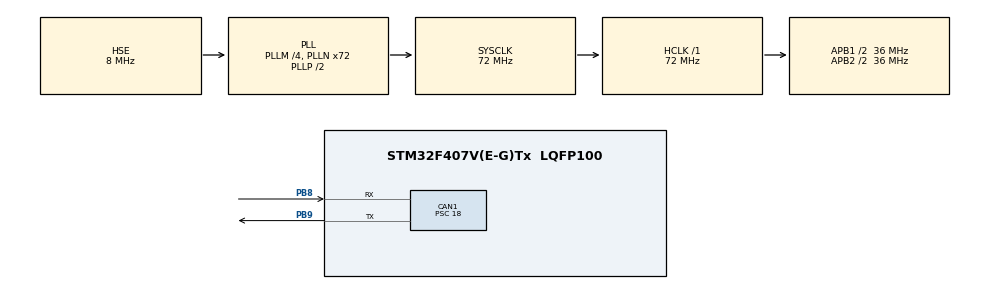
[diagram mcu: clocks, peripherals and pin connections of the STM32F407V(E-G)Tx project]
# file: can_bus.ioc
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CAN1.BS1=CAN_BS1_2TQ
CAN1.CalculateBaudRate=500000
CAN1.CalculateTimeBit=2000
CAN1.CalculateTimeQuantum=500.0
CAN1.Mode=CAN_MODE_LOOPBACK
CAN1.Prescaler=18
Mcu.Family=STM32F4
Mcu.Name=STM32F407V(E-G)Tx
Mcu.Package=LQFP100
NVIC.CAN1_RX0_IRQn=true\:0\:0\:false\:false\:true\:true\:true\:true
NVIC.PriorityGroup=NVIC_PRIORITYGROUP_0
PB8.Mode=CAN_Activate
PB8.Signal=CAN1_RX
PB9.Mode=CAN_Activate
PB9.Signal=CAN1_TX
PH0-OSC_IN.Mode=HSE-External-Oscillator
PH0-OSC_IN.Signal=RCC_OSC_IN
PH1-OSC_OUT.Mode=HSE-External-Oscillator
PH1-OSC_OUT.Signal=RCC_OSC_OUT
ProjectManager.HeapSize=0x200
ProjectManager.StackSize=0x400
ProjectManager.TargetToolchain=STM32CubeIDE
RCC.48MHZClocksFreq_Value=20571428.57142857
RCC.AHBFreq_Value=72000000
RCC.APB1CLKDivider=RCC_HCLK_DIV2
RCC.APB1Freq_Value=36000000
RCC.APB1TimFreq_Value=72000000
RCC.APB2CLKDivider=RCC_HCLK_DIV2
RCC.APB2Freq_Value=36000000
RCC.APB2TimFreq_Value=72000000
RCC.CortexFreq_Value=72000000
RCC.HCLKFreq_Value=72000000
RCC.HSE_VALUE=8000000
RCC.HSI_VALUE=16000000
RCC.LSE_VALUE=32768
RCC.PLLM=4
RCC.PLLN=72
RCC.PLLQ=7
RCC.PLLSourceVirtual=RCC_PLLSOURCE_HSE
RCC.SYSCLKFreq_VALUE=72000000
RCC.SYSCLKSource=RCC_SYSCLKSOURCE_PLLCLK
RCC.VCOOutputFreq_Value=144000000
board=STM32F407G-DISC1

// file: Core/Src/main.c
/* USER CODE BEGIN Header */
/**
  ******************************************************************************
  * @file           : main.c
  * @brief          : Main program body
  ******************************************************************************
  * @attention
  *
  * Copyright (c) 2023 STMicroelectronics.
  * All rights reserved.
  *
  * This software is licensed under terms that can be found in the LICENSE file
  * in the root directory of this software component.
  * If no LICENSE file comes with this software, it is provided AS-IS.
  *
  ******************************************************************************
  */
/* USER CODE END Header */
#include "main.h"

CAN_HandleTypeDef hcan1;

/* USER CODE BEGIN PV */
uint8_t RxData[8];
CAN_RxHeaderTypeDef RxHeader;
uint8_t TxData[8];
CAN_TxHeaderTypeDef TxHeader;
/* USER CODE END PV */

void SystemClock_Config(void);
static void MX_GPIO_Init(void);
static void MX_CAN1_Init(void);

int main(void)
{

  /* MCU Configuration--------------------------------------------------------*/

  /* Reset of all peripherals, Initializes the Flash interface and the Systick. */
  HAL_Init();

  /* Configure the system clock */
  SystemClock_Config();

  /* Initialize all configured peripherals */
  MX_GPIO_Init();
  MX_CAN1_Init();
  /* USER CODE BEGIN 2 */
  if(HAL_CAN_Start(&hcan1) != HAL_OK)
	  Error_Handler();

  if(HAL_CAN_ActivateNotification(&hcan1, CAN_IT_RX_FIFO0_MSG_PENDING) != HAL_OK)
	  Error_Handler();

  uint32_t TxMailBoxNum;

  TxData[0] = 'X';

  TxHeader.DLC = 1;
  TxHeader.RTR = CAN_RTR_DATA;
  TxHeader.IDE = CAN_ID_STD;
  TxHeader.ExtId = 0x00;
  TxHeader.StdId = 0x0AD;
  TxHeader.TransmitGlobalTime = DISABLE;

  if(HAL_CAN_AddTxMessage(&hcan1, &TxHeader, TxData, &TxMailBoxNum) != HAL_OK)
	  Error_Handler();

  TxData[0] = 'D';
  TxData[1] = 'E';
  TxData[2] = 'S';
  TxData[3] = 'D';

  TxHeader.DLC = 4;
  TxHeader.RTR = CAN_RTR_DATA;
  TxHeader.IDE = CAN_ID_STD;
  TxHeader.ExtId = 0x00;
  TxHeader.StdId = 0x0AF;
  TxHeader.TransmitGlobalTime = DISABLE;

  if(HAL_CAN_AddTxMessage(&hcan1, &TxHeader, TxData, &TxMailBoxNum) != HAL_OK)
	  Error_Handler();

  TxData[0] = 'S';
  TxData[1] = 'U';
  TxData[2] = 'N';
  TxData[3] = 'B';
  TxData[4] = 'E';
  TxData[5] = 'A';
  TxData[6] = 'M';

  TxHeader.DLC = 7;
  TxHeader.RTR = CAN_RTR_DATA;
  TxHeader.IDE = CAN_ID_STD;
  TxHeader.ExtId = 0x00;
  TxHeader.StdId = 0x0AB;
  TxHeader.TransmitGlobalTime = DISABLE;

  if(HAL_CAN_AddTxMessage(&hcan1, &TxHeader, TxData, &TxMailBoxNum) != HAL_OK)
	  Error_Handler();

  /* USER CODE END 2 */

  /* Infinite loop */
  while (1)
  {

  }
}

void SystemClock_Config(void)
{
  RCC_OscInitTypeDef RCC_OscInitStruct = {0};
  RCC_ClkInitTypeDef RCC_ClkInitStruct = {0};

  /** Configure the main internal regulator output voltage
  */
  __HAL_RCC_PWR_CLK_ENABLE();
  __HAL_PWR_VOLTAGESCALING_CONFIG(PWR_REGULATOR_VOLTAGE_SCALE1);

  /** Initializes the RCC Oscillators according to the specified parameters
  * in the RCC_OscInitTypeDef structure.
  */
  RCC_OscInitStruct.OscillatorType = RCC_OSCILLATORTYPE_HSE;
  RCC_OscInitStruct.HSEState = RCC_HSE_ON;
  RCC_OscInitStruct.PLL.PLLState = RCC_PLL_ON;
  RCC_OscInitStruct.PLL.PLLSource = RCC_PLLSOURCE_HSE;
  RCC_OscInitStruct.PLL.PLLM = 4;
  RCC_OscInitStruct.PLL.PLLN = 72;
  RCC_OscInitStruct.PLL.PLLP = RCC_PLLP_DIV2;
  RCC_OscInitStruct.PLL.PLLQ = 7;
  if (HAL_RCC_OscConfig(&RCC_OscInitStruct) != HAL_OK)
  {
    Error_Handler();
  }

  /** Initializes the CPU, AHB and APB buses clocks
  */
  RCC_ClkInitStruct.ClockType = RCC_CLOCKTYPE_HCLK|RCC_CLOCKTYPE_SYSCLK
                              |RCC_CLOCKTYPE_PCLK1|RCC_CLOCKTYPE_PCLK2;
  RCC_ClkInitStruct.SYSCLKSource = RCC_SYSCLKSOURCE_PLLCLK;
  RCC_ClkInitStruct.AHBCLKDivider = RCC_SYSCLK_DIV1;
  RCC_ClkInitStruct.APB1CLKDivider = RCC_HCLK_DIV2;
  RCC_ClkInitStruct.APB2CLKDivider = RCC_HCLK_DIV2;

  if (HAL_RCC_ClockConfig(&RCC_ClkInitStruct, FLASH_LATENCY_2) != HAL_OK)
  {
    Error_Handler();
  }
}

static void MX_CAN1_Init(void)
{

  hcan1.Instance = CAN1;
  hcan1.Init.Prescaler = 18;
  hcan1.Init.Mode = CAN_MODE_LOOPBACK;
  hcan1.Init.SyncJumpWidth = CAN_SJW_1TQ;
  hcan1.Init.TimeSeg1 = CAN_BS1_2TQ;
  hcan1.Init.TimeSeg2 = CAN_BS2_1TQ;
  hcan1.Init.TimeTriggeredMode = DISABLE;
  hcan1.Init.AutoBusOff = DISABLE;
  hcan1.Init.AutoWakeUp = DISABLE;
  hcan1.Init.AutoRetransmission = DISABLE;
  hcan1.Init.ReceiveFifoLocked = DISABLE;
  hcan1.Init.TransmitFifoPriority = DISABLE;
  if (HAL_CAN_Init(&hcan1) != HAL_OK)
  {
    Error_Handler();
  }
  /* USER CODE BEGIN CAN1_Init 2 */

  CAN_FilterTypeDef FilterConfig;
  FilterConfig.SlaveStartFilterBank = 14;
  FilterConfig.FilterBank = 6;
  FilterConfig.FilterActivation = CAN_FILTER_ENABLE;
  FilterConfig.FilterFIFOAssignment = CAN_RX_FIFO0;
  FilterConfig.FilterScale = CAN_FILTERSCALE_32BIT;
  FilterConfig.FilterMode = CAN_FILTERMODE_IDMASK;
  FilterConfig.FilterMaskIdLow = 0x0000;
  FilterConfig.FilterMaskIdHigh = 0xFF00; //0x7F8 << 5;
  FilterConfig.FilterIdLow = 0x0000;
  FilterConfig.FilterIdHigh = 0x1500; //0x0A8 << 5;

  if(HAL_CAN_ConfigFilter(&hcan1, &FilterConfig) != HAL_OK)
	  Error_Handler();

  /* USER CODE END CAN1_Init 2 */

}

static void MX_GPIO_Init(void)
{

  /* GPIO Ports Clock Enable */
  __HAL_RCC_GPIOH_CLK_ENABLE();
  __HAL_RCC_GPIOB_CLK_ENABLE();

}

/* USER CODE BEGIN 4 */
void HAL_CAN_RxFifo0MsgPendingCallback(CAN_HandleTypeDef *hcan)
{
	if(HAL_CAN_GetRxMessage(&hcan1, CAN_RX_FIFO0, &RxHeader, RxData) != HAL_OK)
		Error_Handler();
}

/* USER CODE END 4 */

void Error_Handler(void)
{
  __disable_irq();
  while (1)
  {
  }
}
